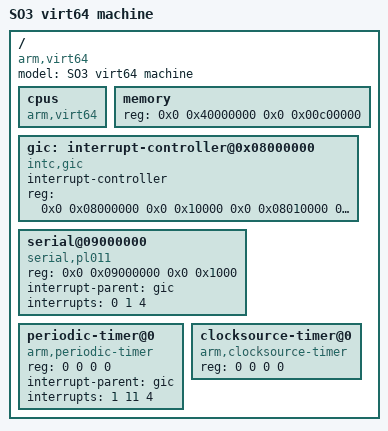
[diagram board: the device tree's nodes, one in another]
/*
 * Copyright (C) 2014-2019 Daniel Rossier <daniel.rossier@heig-vd.ch>
 * 
 * This program is free software; you can redistribute it and/or modify
 * it under the terms of the GNU General Public License version 2 as
 * published by the Free Software Foundation.
 *
 * This program is distributed in the hope that it will be useful,
 * but WITHOUT ANY WARRANTY; without even the implied warranty of
 * MERCHANTABILITY or FITNESS FOR A PARTICULAR PURPOSE.  See the
 * GNU General Public License for more details.
 *
 * You should have received a copy of the GNU General Public License
 * along with this program; if not, write to the Free Software
 * Foundation, Inc., 51 Franklin St, Fifth Floor, Boston, MA  02110-1301  USA
 *
 */
 
/dts-v1/;

/ {
	model = "SO3 virt64 machine";
	compatible = "arm,virt64";
	
	#address-cells = <2>;
	#size-cells = <2>;
	
	cpus {
		device_type = "cpu";
		compatible = "arm,virt64";
	};
	
	memory {
		device_type = "memory";
		reg = <0x0 0x40000000 0x0 0x00c00000>; /* 12 MB for the hypervisor */
	};

	/* GIC interrupt controller */
	gic:interrupt-controller@0x08000000 {
		compatible = "intc,gic";
		interrupt-controller;
		#interrupt-cells = <3>;
		/* GIC dist, cpu */
		reg = <0x0 0x08000000 0x0 0x10000 
		       0x0 0x08010000 0x0 0x10000>;
		
		status = "ok";
	};
 
	/* virt64 console UART */
	serial@09000000 {
		compatible = "serial,pl011";
		reg = <0x0 0x09000000 0x0 0x1000>;
		interrupt-parent = <&gic>;
		interrupts = <0 1 4>;
		status = "ok";
	};

	/* Periodic timer based on ARM CP15 timer */
	periodic-timer@0 {
		compatible = "arm,periodic-timer";
		reg = <0 0 0 0>;
		interrupt-parent = <&gic>;
		
		/* Choose IRQ 10 with VT support or 11 without */
		interrupts = <1 11 4>;
		status = "ok";
	};
	
	/* Clocksource free-running timer based on ARM CP15 timer */
	clocksource-timer@0 {
		compatible = "arm,clocksource-timer";
		reg = <0 0 0 0>;
		status = "ok";
	};
 	
};
